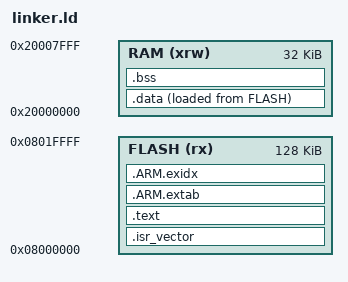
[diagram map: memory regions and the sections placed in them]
/* EFW hwtest - STM32G431RBT6 (CT117E-M4, Lanqiao Cup board)
 * Flash 128K @0x08000000, SRAM 32K @0x20000000 (CCM 10K unused)
 */
ENTRY(Reset_Handler)

MEMORY
{
  FLASH (rx)  : ORIGIN = 0x08000000, LENGTH = 128K
  RAM   (xrw) : ORIGIN = 0x20000000, LENGTH = 32K
}

_estack = ORIGIN(RAM) + LENGTH(RAM);

SECTIONS
{
  .isr_vector :
  {
    . = ALIGN(4);
    KEEP(*(.isr_vector))
    . = ALIGN(4);
  } > FLASH

  .text :
  {
    . = ALIGN(4);
    *(.text*)
    *(.rodata*)
    *(.glue_7) *(.glue_7t)
    . = ALIGN(4);
  } > FLASH

  .ARM.extab :
  {
    *(.ARM.extab* .gnu.linkonce.armextab.*)
  } > FLASH

  .ARM.exidx :
  {
    __exidx_start = .;
    *(.ARM.exidx*)
    __exidx_end = .;
  } > FLASH

  _sidata = LOADADDR(.data);
  .data :
  {
    . = ALIGN(4);
    _sdata = .;
    *(.data*)
    . = ALIGN(4);
    _edata = .;
  } > RAM AT> FLASH

  .bss (NOLOAD) :
  {
    . = ALIGN(4);
    _sbss = .;
    *(.bss*)
    *(COMMON)
    . = ALIGN(4);
    _ebss = .;
  } > RAM
}
